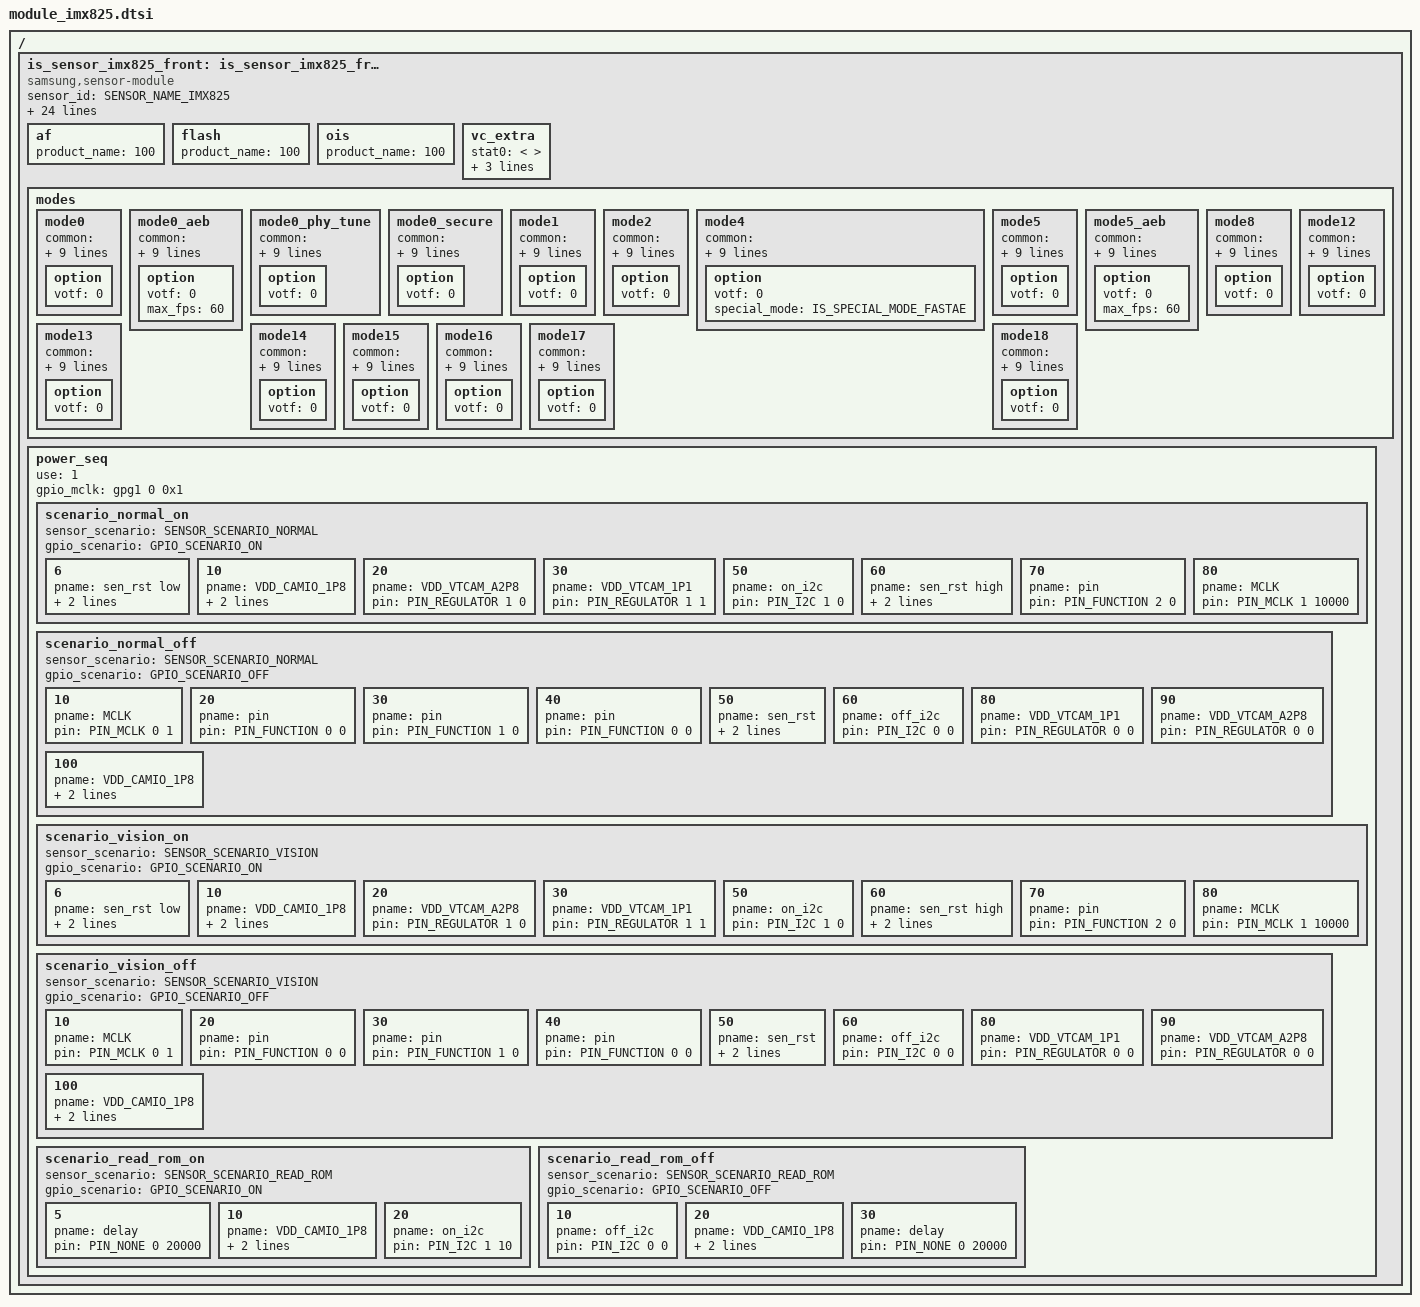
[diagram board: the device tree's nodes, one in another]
/*
 * SAMSUNG EXYNOSxxxx board camera device tree source
 *
 * Copyright (c) 2025 Samsung Electronics Co., Ltd.
 *		http://www.samsung.com
 *
 * This program is free software; you can redistribute it and/or modify
 * it under the terms of the GNU General Public License version 2 as
 * published by the Free Software Foundation.
 */

#include <dt-bindings/camera/exynos_is_dt.h>

/ {
	fragment@camera {
		target-path = "/";
		__overlay__ {
			is_sensor_imx825_front: is_sensor_imx825_front@1a {
				compatible = "samsung,sensor-module";

				/* common */
				sensor_id = <SENSOR_NAME_IMX825>;
				active_width = <4000>;
				active_height = <3000>;
				margin_left = <0>;
				margin_right = <0>;
				margin_top = <0>;
				margin_bottom = <0>;
				max_framerate = <240>;
				bitwidth = <10>;
				use_retention_mode = <SENSOR_RETENTION_UNSUPPORTED>;
				sensor_maker = "SONY";
				sensor_name = "IMX825";
				setfile_name = "setfile_imx825.bin";

				status = "okay";

				/* board */
				pinctrl-names = "pin0", "pin1", "pin2", "release";
				pinctrl-0 = <>;
				pinctrl-1 = <&sensor_mclk0_out>;
				pinctrl-2 = <&sensor_mclk0_fn>;
				pinctrl-3 = <>;

				position = <1>;	/* Rear:0. Front:1. Rear_sub:2. Secure:3. */
				id = <1>; /* is_sensor id */
				mclk_ch = <0>;
				mclk_freq = <19200>;
				sensor_i2c_ch = <5>; /* SENSOR_CONTROL_I2C5 */

				/* vendor */
				rom_id = <1>;
				rom_cal_index = <0>;

				/* peri*/
				af {
					product_name = <100>; /* NOTHING */
				};

				flash {
					product_name = <100>; /* NOTHING */
				};

				ois {
					product_name = <100>; /* NOTHING */
				};

				vc_extra {
					/* ex) statX = <stat_type, sensor_mode, max_width, max_height, max_element> */
					stat0 = </* not available */>;		/* VC_BUF_DATA_TYPE_SENSOR_STAT1 */
					stat1 = </* not available */>;		/* VC_BUF_DATA_TYPE_GENERAL_STAT1 */
					stat2 = </* not available */>;		/* VC_BUF_DATA_TYPE_SENSOR_STAT2 */
					stat3 = </* not available */>;		/* VC_BUF_DATA_TYPE_GENERAL_STAT2 */
				};

				modes {
					/* common = <width, height, fps, settle, mode, lane, speed, interleave, lrte, pd_mode> */
					/* vcX = <map, hwformat, width, height, hwformat, type, width, height> */

					mode0 {
						common = <4000 3000 60 0 0 CSI_DATA_LANES_4 2327 CSI_MODE_VC_DT LRTE_DISABLE PD_NONE>;
						vc0 = </* in */ 0 HW_FORMAT_RAW10 DATA_IMG 4000 3000	/* out */ HW_FORMAT_RAW10 VC_NOTHING 4000 3000>;
						vc1 = </* in */ 1 HW_FORMAT_UNKNOWN DATA_NONE 0 0		/* out */ HW_FORMAT_UNKNOWN VC_NOTHING 0 0>;
						vc2 = </* in */ 2 HW_FORMAT_UNKNOWN DATA_NONE 0 0		/* out */ HW_FORMAT_UNKNOWN VC_NOTHING 0 0>;
						vc3 = </* in */ 3 HW_FORMAT_UNKNOWN DATA_NONE 0 0		/* out */ HW_FORMAT_UNKNOWN VC_NOTHING 0 0>;
						option { votf = <0>; };
					};
					mode0_aeb {
						common = <4000 3000 60 0 0 CSI_DATA_LANES_4 2327 CSI_MODE_VC_DT LRTE_DISABLE PD_NONE EX_AEB>;
						vc0 = </* in */ 0 HW_FORMAT_RAW10 DATA_IMG 4000 3000	/* out */ HW_FORMAT_RAW10 VC_NOTHING 4000 3000>;
						vc1 = </* in */ 2 HW_FORMAT_RAW10 DATA_IMG 4000 3000	/* out */ HW_FORMAT_RAW10 VC_NOTHING 4000 3000>;
						vc2 = </* in */ 1 HW_FORMAT_UNKNOWN DATA_NONE 0 0		/* out */ HW_FORMAT_UNKNOWN VC_NOTHING 0 0>;
						vc3 = </* in */ 3 HW_FORMAT_UNKNOWN DATA_NONE 0 0		/* out */ HW_FORMAT_UNKNOWN VC_NOTHING 0 0>;
						option { votf = <0>; max_fps = <60>; };
					};
					mode0_phy_tune {
						common = <4000 3000 60 0 0 CSI_DATA_LANES_4 2327 CSI_MODE_VC_DT LRTE_DISABLE PD_NONE EX_PHY_TUNE>;
						vc0 = </* in */ 0 HW_FORMAT_RAW10 DATA_IMG 4000 3000	/* out */ HW_FORMAT_RAW10 VC_NOTHING 4000 3000>;
						vc1 = </* in */ 1 HW_FORMAT_UNKNOWN DATA_NONE 0 0		/* out */ HW_FORMAT_UNKNOWN VC_NOTHING 0 0>;
						vc2 = </* in */ 2 HW_FORMAT_UNKNOWN DATA_NONE 0 0		/* out */ HW_FORMAT_UNKNOWN VC_NOTHING 0 0>;
						vc3 = </* in */ 3 HW_FORMAT_UNKNOWN DATA_NONE 0 0		/* out */ HW_FORMAT_UNKNOWN VC_NOTHING 0 0>;
						option { votf = <0>; };
					};
					mode0_secure {
						common = <4000 3000 60 0 0 CSI_DATA_LANES_4 2327 CSI_MODE_VC_DT LRTE_DISABLE PD_NONE EX_PDAF_OFF>;
						vc0 = </* in */ 0 HW_FORMAT_RAW10 DATA_IMG 4000 3000	/* out */ HW_FORMAT_RAW10 VC_NOTHING 4000 3000>;
						vc1 = </* in */ 1 HW_FORMAT_UNKNOWN DATA_NONE 0 0		/* out */ HW_FORMAT_UNKNOWN VC_NOTHING 0 0>;
						vc2 = </* in */ 2 HW_FORMAT_UNKNOWN DATA_NONE 0 0		/* out */ HW_FORMAT_UNKNOWN VC_NOTHING 0 0>;
						vc3 = </* in */ 3 HW_FORMAT_UNKNOWN DATA_NONE 0 0		/* out */ HW_FORMAT_UNKNOWN VC_NOTHING 0 0>;
						option { votf = <0>; };
					};
					mode1 {
						common = <4000 3000 30 0 1 CSI_DATA_LANES_4 2327 CSI_MODE_VC_DT LRTE_DISABLE PD_NONE>;
						vc0 = </* in */ 0 HW_FORMAT_RAW12 DATA_IMG 4000 3000	/* out */ HW_FORMAT_RAW12 VC_NOTHING 4000 3000>;
						vc1 = </* in */ 1 HW_FORMAT_UNKNOWN DATA_NONE 0 0		/* out */ HW_FORMAT_UNKNOWN VC_NOTHING 0 0>;
						vc2 = </* in */ 2 HW_FORMAT_UNKNOWN DATA_NONE 0 0		/* out */ HW_FORMAT_UNKNOWN VC_NOTHING 0 0>;
						vc3 = </* in */ 3 HW_FORMAT_UNKNOWN DATA_NONE 0 0		/* out */ HW_FORMAT_UNKNOWN VC_NOTHING 0 0>;
						option { votf = <0>; };
					};
					mode2 {
						common = <4000 3000 24 0 2 CSI_DATA_LANES_4 2327 CSI_MODE_VC_DT LRTE_DISABLE PD_NONE EX_LN>;
						vc0 = </* in */ 0 HW_FORMAT_RAW10 DATA_IMG 4000 3000	/* out */ HW_FORMAT_RAW10 VC_NOTHING 4000 3000>;
						vc1 = </* in */ 1 HW_FORMAT_UNKNOWN DATA_NONE 0 0		/* out */ HW_FORMAT_UNKNOWN VC_NOTHING 0 0>;
						vc2 = </* in */ 2 HW_FORMAT_UNKNOWN DATA_NONE 0 0		/* out */ HW_FORMAT_UNKNOWN VC_NOTHING 0 0>;
						vc3 = </* in */ 3 HW_FORMAT_UNKNOWN DATA_NONE 0 0		/* out */ HW_FORMAT_UNKNOWN VC_NOTHING 0 0>;
						option { votf = <0>; };
					};
					mode4 {
						common = <2000 1500 120 0 4 CSI_DATA_LANES_4 2392 CSI_MODE_VC_DT LRTE_DISABLE PD_NONE>;
						vc0 = </* in */ 0 HW_FORMAT_RAW10 DATA_IMG 2000 1500	/* out */ HW_FORMAT_RAW10 VC_NOTHING 2000 1500>;
						vc1 = </* in */ 1 HW_FORMAT_UNKNOWN DATA_NONE 0 0		/* out */ HW_FORMAT_UNKNOWN VC_NOTHING 0 0>;
						vc2 = </* in */ 2 HW_FORMAT_UNKNOWN DATA_NONE 0 0		/* out */ HW_FORMAT_UNKNOWN VC_NOTHING 0 0>;
						vc3 = </* in */ 3 HW_FORMAT_UNKNOWN DATA_NONE 0 0		/* out */ HW_FORMAT_UNKNOWN VC_NOTHING 0 0>;
						option { votf = <0>; special_mode = <IS_SPECIAL_MODE_FASTAE>; };
					};
					mode5 {
						common = <4000 2252 60 0 5 CSI_DATA_LANES_4 2327 CSI_MODE_VC_DT LRTE_DISABLE PD_NONE>;
						vc0 = </* in */ 0 HW_FORMAT_RAW10 DATA_IMG 4000 2252	/* out */ HW_FORMAT_RAW10 VC_NOTHING 4000 2252>;
						vc1 = </* in */ 1 HW_FORMAT_UNKNOWN DATA_NONE 0 0		/* out */ HW_FORMAT_UNKNOWN VC_NOTHING 0 0>;
						vc2 = </* in */ 2 HW_FORMAT_UNKNOWN DATA_NONE 0 0		/* out */ HW_FORMAT_UNKNOWN VC_NOTHING 0 0>;
						vc3 = </* in */ 3 HW_FORMAT_UNKNOWN DATA_NONE 0 0		/* out */ HW_FORMAT_UNKNOWN VC_NOTHING 0 0>;
						option { votf = <0>; };
					};
					mode5_aeb {
						common = <4000 2252 60 0 5 CSI_DATA_LANES_4 2327 CSI_MODE_VC_DT LRTE_DISABLE PD_NONE EX_AEB>;
						vc0 = </* in */ 0 HW_FORMAT_RAW10 DATA_IMG 4000 2252	/* out */ HW_FORMAT_RAW10 VC_NOTHING 4000 2252>;
						vc1 = </* in */ 2 HW_FORMAT_RAW10 DATA_IMG 4000 2252	/* out */ HW_FORMAT_RAW10 VC_NOTHING 4000 2252>;
						vc2 = </* in */ 1 HW_FORMAT_UNKNOWN DATA_NONE 0 0		/* out */ HW_FORMAT_UNKNOWN VC_NOTHING 0 0>;
						vc3 = </* in */ 3 HW_FORMAT_UNKNOWN DATA_NONE 0 0		/* out */ HW_FORMAT_UNKNOWN VC_NOTHING 0 0>;
						option { votf = <0>; max_fps = <60>; };
					};
					mode8 {
						common = <4000 2252 60 0 8 CSI_DATA_LANES_4 2327 CSI_MODE_VC_DT LRTE_DISABLE PD_NONE>;
						vc0 = </* in */ 0 HW_FORMAT_RAW12 DATA_IMG 4000 2252	/* out */ HW_FORMAT_RAW12 VC_NOTHING 4000 2252>;
						vc1 = </* in */ 1 HW_FORMAT_UNKNOWN DATA_NONE 0 0		/* out */ HW_FORMAT_UNKNOWN VC_NOTHING 0 0>;
						vc2 = </* in */ 2 HW_FORMAT_UNKNOWN DATA_NONE 0 0		/* out */ HW_FORMAT_UNKNOWN VC_NOTHING 0 0>;
						vc3 = </* in */ 3 HW_FORMAT_UNKNOWN DATA_NONE 0 0		/* out */ HW_FORMAT_UNKNOWN VC_NOTHING 0 0>;
						option { votf = <0>; };
					};
					mode12 {
						common = <2000 1126 30 0 12 CSI_DATA_LANES_4 2392 CSI_MODE_VC_DT LRTE_DISABLE PD_NONE>;
						vc0 = </* in */ 0 HW_FORMAT_RAW10 DATA_IMG 2000 1126	/* out */ HW_FORMAT_RAW10 VC_NOTHING 2000 1126>;
						vc1 = </* in */ 1 HW_FORMAT_UNKNOWN DATA_NONE 0 0		/* out */ HW_FORMAT_UNKNOWN VC_NOTHING 0 0>;
						vc2 = </* in */ 2 HW_FORMAT_UNKNOWN DATA_NONE 0 0		/* out */ HW_FORMAT_UNKNOWN VC_NOTHING 0 0>;
						vc3 = </* in */ 3 HW_FORMAT_UNKNOWN DATA_NONE 0 0		/* out */ HW_FORMAT_UNKNOWN VC_NOTHING 0 0>;
						option { votf = <0>; };
					};
					mode13 {
						common = <2000 1500 30 0 13 CSI_DATA_LANES_4 2392 CSI_MODE_VC_DT LRTE_DISABLE PD_NONE>;
						vc0 = </* in */ 0 HW_FORMAT_RAW10 DATA_IMG 2000 1500	/* out */ HW_FORMAT_RAW10 VC_NOTHING 2000 1500>;
						vc1 = </* in */ 1 HW_FORMAT_UNKNOWN DATA_NONE 0 0		/* out */ HW_FORMAT_UNKNOWN VC_NOTHING 0 0>;
						vc2 = </* in */ 2 HW_FORMAT_UNKNOWN DATA_NONE 0 0		/* out */ HW_FORMAT_UNKNOWN VC_NOTHING 0 0>;
						vc3 = </* in */ 3 HW_FORMAT_UNKNOWN DATA_NONE 0 0		/* out */ HW_FORMAT_UNKNOWN VC_NOTHING 0 0>;
						option { votf = <0>; };
					};
					mode14 {
						common = <3392 2544 30 0 14 CSI_DATA_LANES_4 2327 CSI_MODE_VC_DT LRTE_DISABLE PD_NONE>;
						vc0 = </* in */ 0 HW_FORMAT_RAW10 DATA_IMG 3392 2544	/* out */ HW_FORMAT_RAW10 VC_NOTHING 3392 2544>;
						vc1 = </* in */ 1 HW_FORMAT_UNKNOWN DATA_NONE 0 0		/* out */ HW_FORMAT_UNKNOWN VC_NOTHING 0 0>;
						vc2 = </* in */ 2 HW_FORMAT_UNKNOWN DATA_NONE 0 0		/* out */ HW_FORMAT_UNKNOWN VC_NOTHING 0 0>;
						vc3 = </* in */ 3 HW_FORMAT_UNKNOWN DATA_NONE 0 0		/* out */ HW_FORMAT_UNKNOWN VC_NOTHING 0 0>;
						option { votf = <0>; };
					};
					mode15 {
						common = <3392 1908 30 0 15 CSI_DATA_LANES_4 2327 CSI_MODE_VC_DT LRTE_DISABLE PD_NONE>;
						vc0 = </* in */ 0 HW_FORMAT_RAW10 DATA_IMG 3392 1908	/* out */ HW_FORMAT_RAW10 VC_NOTHING 3392 1908>;
						vc1 = </* in */ 1 HW_FORMAT_UNKNOWN DATA_NONE 0 0		/* out */ HW_FORMAT_UNKNOWN VC_NOTHING 0 0>;
						vc2 = </* in */ 2 HW_FORMAT_UNKNOWN DATA_NONE 0 0		/* out */ HW_FORMAT_UNKNOWN VC_NOTHING 0 0>;
						vc3 = </* in */ 3 HW_FORMAT_UNKNOWN DATA_NONE 0 0		/* out */ HW_FORMAT_UNKNOWN VC_NOTHING 0 0>;
						option { votf = <0>; };
					};
					mode16 {
						common = <1696 1272 30 0 16 CSI_DATA_LANES_4 2392 CSI_MODE_VC_DT LRTE_DISABLE PD_NONE>;
						vc0 = </* in */ 0 HW_FORMAT_RAW10 DATA_IMG 1696 1272	/* out */ HW_FORMAT_RAW10 VC_NOTHING 1696 1272>;
						vc1 = </* in */ 1 HW_FORMAT_UNKNOWN DATA_NONE 0 0		/* out */ HW_FORMAT_UNKNOWN VC_NOTHING 0 0>;
						vc2 = </* in */ 2 HW_FORMAT_UNKNOWN DATA_NONE 0 0		/* out */ HW_FORMAT_UNKNOWN VC_NOTHING 0 0>;
						vc3 = </* in */ 3 HW_FORMAT_UNKNOWN DATA_NONE 0 0		/* out */ HW_FORMAT_UNKNOWN VC_NOTHING 0 0>;
						option { votf = <0>; };
					};
					mode17 {
						common = <1696 954 30 0 17 CSI_DATA_LANES_4 2392 CSI_MODE_VC_DT LRTE_DISABLE PD_NONE>;
						vc0 = </* in */ 0 HW_FORMAT_RAW10 DATA_IMG 1696 954	/* out */ HW_FORMAT_RAW10 VC_NOTHING 1696 954>;
						vc1 = </* in */ 1 HW_FORMAT_UNKNOWN DATA_NONE 0 0		/* out */ HW_FORMAT_UNKNOWN VC_NOTHING 0 0>;
						vc2 = </* in */ 2 HW_FORMAT_UNKNOWN DATA_NONE 0 0		/* out */ HW_FORMAT_UNKNOWN VC_NOTHING 0 0>;
						vc3 = </* in */ 3 HW_FORMAT_UNKNOWN DATA_NONE 0 0		/* out */ HW_FORMAT_UNKNOWN VC_NOTHING 0 0>;
						option { votf = <0>; };
					};
					mode18 {
						common = <2000 1126 120 0 18 CSI_DATA_LANES_4 2392 CSI_MODE_VC_DT LRTE_DISABLE PD_NONE>;
						vc0 = </* in */ 0 HW_FORMAT_RAW10 DATA_IMG 2000 1126	/* out */ HW_FORMAT_RAW10 VC_NOTHING 2000 1126>;
						vc1 = </* in */ 1 HW_FORMAT_UNKNOWN DATA_NONE 0 0		/* out */ HW_FORMAT_UNKNOWN VC_NOTHING 0 0>;
						vc2 = </* in */ 2 HW_FORMAT_UNKNOWN DATA_NONE 0 0		/* out */ HW_FORMAT_UNKNOWN VC_NOTHING 0 0>;
						vc3 = </* in */ 3 HW_FORMAT_UNKNOWN DATA_NONE 0 0		/* out */ HW_FORMAT_UNKNOWN VC_NOTHING 0 0>;
						option { votf = <0>; };
					};
				};

				power_seq {
					use = <1>;
					gpio_mclk = <&gpg1 0 0x1>;
					scenario_normal_on {
						sensor_scenario = <SENSOR_SCENARIO_NORMAL>;
						gpio_scenario = <GPIO_SCENARIO_ON>;

						/* A start node number should be over the 10 for reserved number 0~9. */
						/* pname = "name"; pin = <act value delay voltage>; gpio = <gpx# # 0x1>; */
						6 { pname = "sen_rst low"; pin = <PIN_OUTPUT 0 0>; gpio = <&gpp4 0 0x1>; };
						10 { pname = "VDD_CAMIO_1P8"; pin = <PIN_OUTPUT 1 0>; gpio = <&gpm6 0 0x1>; };
						20 { pname = "VDD_VTCAM_A2P8"; pin = <PIN_REGULATOR 1 0>; };
						30 { pname = "VDD_VTCAM_1P1"; pin = <PIN_REGULATOR 1 1>; };
						50 { pname = "on_i2c"; pin = <PIN_I2C 1 0>; };
						60 { pname = "sen_rst high"; pin = <PIN_OUTPUT 1 0>; gpio = <&gpp4 0 0x1>; };
						70 { pname = "pin"; pin = <PIN_FUNCTION 2 0>; };
						80 { pname = "MCLK"; pin = <PIN_MCLK 1 10000>; };
					};

					scenario_normal_off {
						sensor_scenario = <SENSOR_SCENARIO_NORMAL>;
						gpio_scenario = <GPIO_SCENARIO_OFF>;

						/* A start node number should be over the 10 for reserved number 0~9. */
						/* pname = "name"; pin = <act value delay voltage>; gpio = <gpx# # 0x1>; */
						10 { pname = "MCLK"; pin = <PIN_MCLK 0 1>; };
						20 { pname = "pin"; pin = <PIN_FUNCTION 0 0>; };
						30 { pname = "pin"; pin = <PIN_FUNCTION 1 0>; };
						40 { pname = "pin"; pin = <PIN_FUNCTION 0 0>; };
						50 { pname = "sen_rst"; pin = <PIN_OUTPUT 0 0>; gpio = <&gpp4 0 0x1>; };
						60 { pname = "off_i2c"; pin = <PIN_I2C 0 0>; };
						80 { pname = "VDD_VTCAM_1P1"; pin = <PIN_REGULATOR 0 0>; };
						90 { pname = "VDD_VTCAM_A2P8"; pin = <PIN_REGULATOR 0 0>; };
						100 { pname = "VDD_CAMIO_1P8"; pin = <PIN_OUTPUT 0 0>; gpio = <&gpm6 0 0x1>; };
					};

					scenario_vision_on {
						sensor_scenario = <SENSOR_SCENARIO_VISION>;
						gpio_scenario = <GPIO_SCENARIO_ON>;

						/* A start node number should be over the 10 for reserved number 0~9. */
						/* pname = "name"; pin = <act value delay voltage>; gpio = <gpx# # 0x1>; */
						6 { pname = "sen_rst low"; pin = <PIN_OUTPUT 0 0>; gpio = <&gpp4 0 0x1>; };
						10 { pname = "VDD_CAMIO_1P8"; pin = <PIN_OUTPUT 1 0>; gpio = <&gpm6 0 0x1>; };
						20 { pname = "VDD_VTCAM_A2P8"; pin = <PIN_REGULATOR 1 0>; };
						30 { pname = "VDD_VTCAM_1P1"; pin = <PIN_REGULATOR 1 1>; };
						50 { pname = "on_i2c"; pin = <PIN_I2C 1 0>; };
						60 { pname = "sen_rst high"; pin = <PIN_OUTPUT 1 0>; gpio = <&gpp4 0 0x1>; };
						70 { pname = "pin"; pin = <PIN_FUNCTION 2 0>; };
						80 { pname = "MCLK"; pin = <PIN_MCLK 1 10000>; };
					};

					scenario_vision_off {
						sensor_scenario = <SENSOR_SCENARIO_VISION>;
						gpio_scenario = <GPIO_SCENARIO_OFF>;

						/* A start node number should be over the 10 for reserved number 0~9. */
						/* pname = "name"; pin = <act value delay voltage>; gpio = <gpx# # 0x1>; */
						10 { pname = "MCLK"; pin = <PIN_MCLK 0 1>; };
						20 { pname = "pin"; pin = <PIN_FUNCTION 0 0>; };
						30 { pname = "pin"; pin = <PIN_FUNCTION 1 0>; };
						40 { pname = "pin"; pin = <PIN_FUNCTION 0 0>; };
						50 { pname = "sen_rst"; pin = <PIN_OUTPUT 0 0>; gpio = <&gpp4 0 0x1>; };
						60 { pname = "off_i2c"; pin = <PIN_I2C 0 0>; };
						80 { pname = "VDD_VTCAM_1P1"; pin = <PIN_REGULATOR 0 0>; };
						90 { pname = "VDD_VTCAM_A2P8"; pin = <PIN_REGULATOR 0 0>; };
						100 { pname = "VDD_CAMIO_1P8"; pin = <PIN_OUTPUT 0 0>; gpio = <&gpm6 0 0x1>; };
					};

					scenario_read_rom_on {
						sensor_scenario = <SENSOR_SCENARIO_READ_ROM>;
						gpio_scenario = <GPIO_SCENARIO_ON>;

						/* A start node number should be over the 10 for reserved number 0~9. */
						/* pname = "name"; pin = <act value delay voltage>; gpio = <gpx# # 0x1>; */
						5 { pname = "delay"; pin = <PIN_NONE 0 20000>; };
						10 { pname = "VDD_CAMIO_1P8"; pin = <PIN_OUTPUT 1 7000>; gpio = <&gpm6 0 0x1>; };
						20 { pname = "on_i2c"; pin = <PIN_I2C 1 10>; };
					};

					scenario_read_rom_off {
						sensor_scenario = <SENSOR_SCENARIO_READ_ROM>;
						gpio_scenario = <GPIO_SCENARIO_OFF>;

						/* A start node number should be over the 10 for reserved number 0~9. */
						/* pname = "name"; pin = <act value delay voltage>; gpio = <gpx# # 0x1>; */
						10 { pname = "off_i2c"; pin = <PIN_I2C 0 0>; };
						20 { pname = "VDD_CAMIO_1P8"; pin = <PIN_OUTPUT 0 0>; gpio = <&gpm6 0 0x1>; };
						30 { pname = "delay"; pin = <PIN_NONE 0 20000>; };
					};
				};
			};
		}; /* end of __overlay__ */
	}; /* end of fragment */
}; /* end of root */
